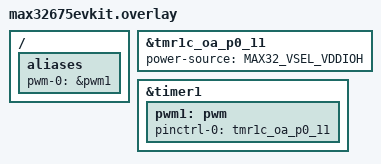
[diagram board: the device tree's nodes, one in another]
/*
 * Copyright (c) 2024 Analog Devices, Inc.
 *
 * SPDX-License-Identifier: Apache-2.0
 */

/ {
	aliases {
		pwm-0 = &pwm1;
	};
};

&tmr1c_oa_p0_11 {
	power-source=<MAX32_VSEL_VDDIOH>;
};

&timer1 {
	status = "okay";
	pwm1: pwm {
		status = "okay";
		pinctrl-0 = <&tmr1c_oa_p0_11>;
		pinctrl-names = "default";
	};
};
